VERSION ""

NS_ :

BS_:

BU_: Vector__XXX

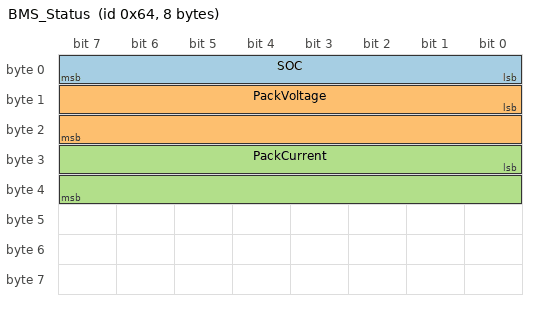
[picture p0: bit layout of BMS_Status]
BO_ 100 BMS_Status: 8 Vector__XXX
 SG_ SOC : 0|8@1+ (1,0) [0|100] "%" Vector__XXX
 SG_ PackVoltage : 8|16@1+ (0.1,0) [0|500] "V" Vector__XXX
 SG_ PackCurrent : 24|16@1- (0.1,0) [-1000|1000] "A" Vector__XXX

BO_ 200 Motor_Status: 8 Vector__XXX
 SG_ MotorRPM : 0|16@1+ (1,0) [0|20000] "rpm" Vector__XXX
 SG_ MotorTemp : 16|8@1- (1,-40) [-40|215] "C" Vector__XXX

BO_ 300 Charger_Status: 8 Vector__XXX
 SG_ ChargeVoltage : 0|16@1+ (0.1,0) [0|500] "V" Vector__XXX
 SG_ ChargeCurrent : 16|16@1+ (0.1,0) [0|1000] "A" Vector__XXX
